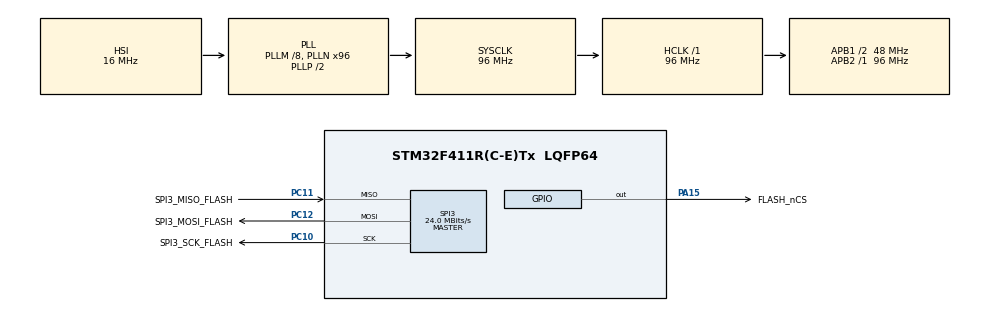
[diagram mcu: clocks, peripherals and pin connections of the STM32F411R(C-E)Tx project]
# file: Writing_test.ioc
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Mcu.Family=STM32F4
Mcu.Name=STM32F411R(C-E)Tx
Mcu.Package=LQFP64
NVIC.PriorityGroup=NVIC_PRIORITYGROUP_4
PA13.Mode=Serial_Wire
PA13.Signal=SYS_JTMS-SWDIO
PA14.Mode=Serial_Wire
PA14.Signal=SYS_JTCK-SWCLK
PA15.GPIO_Label=FLASH_nCS
PA15.GPIO_Speed=GPIO_SPEED_FREQ_HIGH
PA15.PinState=GPIO_PIN_SET
PA15.Signal=GPIO_Output
PC10.GPIO_Label=SPI3_SCK_FLASH
PC10.Mode=Full_Duplex_Master
PC10.Signal=SPI3_SCK
PC11.GPIO_Label=SPI3_MISO_FLASH
PC11.Mode=Full_Duplex_Master
PC11.Signal=SPI3_MISO
PC12.GPIO_Label=SPI3_MOSI_FLASH
PC12.Mode=Full_Duplex_Master
PC12.Signal=SPI3_MOSI
ProjectManager.HeapSize=0x200
ProjectManager.StackSize=0x400
ProjectManager.TargetToolchain=STM32CubeIDE
RCC.48MHZClocksFreq_Value=48000000
RCC.AHBFreq_Value=96000000
RCC.APB1CLKDivider=RCC_HCLK_DIV2
RCC.APB1Freq_Value=48000000
RCC.APB1TimFreq_Value=96000000
RCC.APB2Freq_Value=96000000
RCC.APB2TimFreq_Value=96000000
RCC.CortexFreq_Value=96000000
RCC.HCLKFreq_Value=96000000
RCC.HSE_VALUE=25000000
RCC.HSI_VALUE=16000000
RCC.LSE_VALUE=32768
RCC.PLLM=8
RCC.PLLN=96
RCC.SYSCLKFreq_VALUE=96000000
RCC.SYSCLKSource=RCC_SYSCLKSOURCE_PLLCLK
RCC.VCOOutputFreq_Value=192000000
SPI3.CalculateBaudRate=24.0 MBits/s
SPI3.Direction=SPI_DIRECTION_2LINES
SPI3.Mode=SPI_MODE_MASTER
SPI3.VirtualType=VM_MASTER
board=custom

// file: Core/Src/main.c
/* USER CODE BEGIN Header */
/**
  ******************************************************************************
  * @file           : main.c
  * @brief          : Main program body
  ******************************************************************************
  * @attention
  *
  * Copyright (c) 2024 STMicroelectronics.
  * All rights reserved.
  *
  * This software is licensed under terms that can be found in the LICENSE file
  * in the root directory of this software component.
  * If no LICENSE file comes with this software, it is provided AS-IS.
  *
  ******************************************************************************
  */
/* USER CODE END Header */
#include "main.h"

SPI_HandleTypeDef hspi3;

void SystemClock_Config(void);
static void MX_GPIO_Init(void);
static void MX_SPI3_Init(void);

int main(void)
{

  /* MCU Configuration--------------------------------------------------------*/

  /* Reset of all peripherals, Initializes the Flash interface and the Systick. */
  HAL_Init();

  /* Configure the system clock */
  SystemClock_Config();

  /* Initialize all configured peripherals */
  MX_GPIO_Init();
  MX_SPI3_Init();

  /* Infinite loop */
  /* USER CODE BEGIN WHILE */
  if(!Flash_Init()){
  	  while(1){

  	  }
  }
  Flash_ChipErase();
//  uint8_t mess[20];
//
//  for (int i = 0; i < 20; i++) {
//          mess[i] = i + 1;
//      }
//
//  Flash_Write(0,mess,20);
//  uint8_t test[20];
//
//  for (int i = 0; i < 20; i++) {
//          test[i] = 0;
//      }
//  Flash_Read(0,test,sizeof(mess));
// SALVATAGGIO DI UN ARRAY DI INTERI, FUNZIONA

  float cazzi[20];

  for(int i = 0; i<20; i++){
	  cazzi[i] = (float)i + 1.0;
  }
  Flash_Write_float(0,cazzi,sizeof(cazzi));
  float test[20];
  for (int i = 0; i < 20; i++) {
      test[i] = 0;
  }

  Flash_Read_float(0,test,sizeof(cazzi));

  while (1)
  {
    /* USER CODE END WHILE */

  }
}

void SystemClock_Config(void)
{
  RCC_OscInitTypeDef RCC_OscInitStruct = {0};
  RCC_ClkInitTypeDef RCC_ClkInitStruct = {0};

  /** Configure the main internal regulator output voltage
  */
  __HAL_RCC_PWR_CLK_ENABLE();
  __HAL_PWR_VOLTAGESCALING_CONFIG(PWR_REGULATOR_VOLTAGE_SCALE1);

  /** Initializes the RCC Oscillators according to the specified parameters
  * in the RCC_OscInitTypeDef structure.
  */
  RCC_OscInitStruct.OscillatorType = RCC_OSCILLATORTYPE_HSI;
  RCC_OscInitStruct.HSIState = RCC_HSI_ON;
  RCC_OscInitStruct.HSICalibrationValue = RCC_HSICALIBRATION_DEFAULT;
  RCC_OscInitStruct.PLL.PLLState = RCC_PLL_ON;
  RCC_OscInitStruct.PLL.PLLSource = RCC_PLLSOURCE_HSI;
  RCC_OscInitStruct.PLL.PLLM = 8;
  RCC_OscInitStruct.PLL.PLLN = 96;
  RCC_OscInitStruct.PLL.PLLP = RCC_PLLP_DIV2;
  RCC_OscInitStruct.PLL.PLLQ = 4;
  if (HAL_RCC_OscConfig(&RCC_OscInitStruct) != HAL_OK)
  {
    Error_Handler();
  }

  /** Initializes the CPU, AHB and APB buses clocks
  */
  RCC_ClkInitStruct.ClockType = RCC_CLOCKTYPE_HCLK|RCC_CLOCKTYPE_SYSCLK
                              |RCC_CLOCKTYPE_PCLK1|RCC_CLOCKTYPE_PCLK2;
  RCC_ClkInitStruct.SYSCLKSource = RCC_SYSCLKSOURCE_PLLCLK;
  RCC_ClkInitStruct.AHBCLKDivider = RCC_SYSCLK_DIV1;
  RCC_ClkInitStruct.APB1CLKDivider = RCC_HCLK_DIV2;
  RCC_ClkInitStruct.APB2CLKDivider = RCC_HCLK_DIV1;

  if (HAL_RCC_ClockConfig(&RCC_ClkInitStruct, FLASH_LATENCY_3) != HAL_OK)
  {
    Error_Handler();
  }
}

static void MX_SPI3_Init(void)
{

  /* SPI3 parameter configuration*/
  hspi3.Instance = SPI3;
  hspi3.Init.Mode = SPI_MODE_MASTER;
  hspi3.Init.Direction = SPI_DIRECTION_2LINES;
  hspi3.Init.DataSize = SPI_DATASIZE_8BIT;
  hspi3.Init.CLKPolarity = SPI_POLARITY_LOW;
  hspi3.Init.CLKPhase = SPI_PHASE_1EDGE;
  hspi3.Init.NSS = SPI_NSS_SOFT;
  hspi3.Init.BaudRatePrescaler = SPI_BAUDRATEPRESCALER_2;
  hspi3.Init.FirstBit = SPI_FIRSTBIT_MSB;
  hspi3.Init.TIMode = SPI_TIMODE_DISABLE;
  hspi3.Init.CRCCalculation = SPI_CRCCALCULATION_DISABLE;
  hspi3.Init.CRCPolynomial = 10;
  if (HAL_SPI_Init(&hspi3) != HAL_OK)
  {
    Error_Handler();
  }

}

static void MX_GPIO_Init(void)
{
  GPIO_InitTypeDef GPIO_InitStruct = {0};

  /* GPIO Ports Clock Enable */
  __HAL_RCC_GPIOA_CLK_ENABLE();
  __HAL_RCC_GPIOC_CLK_ENABLE();

  /*Configure GPIO pin Output Level */
  HAL_GPIO_WritePin(FLASH_nCS_GPIO_Port, FLASH_nCS_Pin, GPIO_PIN_SET);

  /*Configure GPIO pin : FLASH_nCS_Pin */
  GPIO_InitStruct.Pin = FLASH_nCS_Pin;
  GPIO_InitStruct.Mode = GPIO_MODE_OUTPUT_PP;
  GPIO_InitStruct.Pull = GPIO_NOPULL;
  GPIO_InitStruct.Speed = GPIO_SPEED_FREQ_HIGH;
  HAL_GPIO_Init(FLASH_nCS_GPIO_Port, &GPIO_InitStruct);

}

void Error_Handler(void)
{
  __disable_irq();
  while (1)
  {
  }
}
